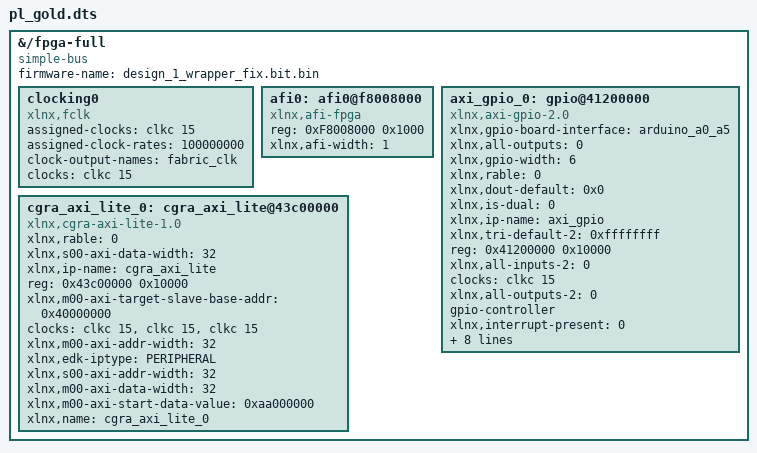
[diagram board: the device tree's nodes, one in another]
/dts-v1/;
/plugin/;

/ {
	fragment@0 {
		target-path = "/fpga-full";
		__overlay__ {
			ranges;
			compatible = "simple-bus";
			#address-cells = <1>;
			#size-cells = <1>;
			firmware-name = "design_1_wrapper_fix.bit.bin";
			clocking0: clocking0 {
				compatible = "xlnx,fclk";
				assigned-clocks = <&clkc 15>;
				assigned-clock-rates = <100000000>;
				#clock-cells = <0>;
				clock-output-names = "fabric_clk";
				clocks = <&clkc 15>;
			};
			afi0: afi0@f8008000 {
				status = "okay";
				compatible = "xlnx,afi-fpga";
				#address-cells = <1>;
				reg = <0xF8008000 0x1000>;
				#size-cells = <0>;
				xlnx,afi-width = <1>;
			};
			axi_gpio_0: gpio@41200000 {
				xlnx,gpio-board-interface = "arduino_a0_a5";
				compatible = "xlnx,axi-gpio-2.0" , "xlnx,xps-gpio-1.00.a";
				xlnx,all-outputs = <0>;
				#gpio-cells = <2>;
				xlnx,gpio-width = <6>;
				xlnx,rable = <0>;
				xlnx,dout-default = <0x0>;
				xlnx,is-dual = <0>;
				xlnx,ip-name = "axi_gpio";
				xlnx,tri-default-2 = <0xffffffff>;
				reg = <0x41200000 0x10000>;
				xlnx,all-inputs-2 = <0>;
				clocks = <&clkc 15>;
				xlnx,all-outputs-2 = <0>;
				gpio-controller;
				xlnx,interrupt-present = <0>;
				xlnx,gpio2-board-interface = "Custom";
				xlnx,edk-iptype = "PERIPHERAL";
				xlnx,dout-default-2 = <0x0>;
				status = "okay";
				xlnx,gpio2-width = <32>;
				clock-names = "s_axi_aclk";
				xlnx,use-board-flow;
				xlnx,tri-default = <0xffffffff>;
				xlnx,name = "axi_gpio_0";
				xlnx,all-inputs = <0>;
			};
			cgra_axi_lite_0: cgra_axi_lite@43c00000 {
				compatible = "xlnx,cgra-axi-lite-1.0";
				xlnx,rable = <0>;
				xlnx,s00-axi-data-width = <32>;
				xlnx,ip-name = "cgra_axi_lite";
				reg = <0x43c00000 0x10000>;
				xlnx,m00-axi-target-slave-base-addr = <0x40000000>;
				clocks = <&clkc 15>, <&clkc 15>, <&clkc 15>;
				xlnx,m00-axi-addr-width = <32>;
				xlnx,edk-iptype = "PERIPHERAL";
				status = "okay";
				clock-names = "clk_i" , "m00_axi_aclk" , "s00_axi_aclk";
				xlnx,s00-axi-addr-width = <32>;
				xlnx,m00-axi-data-width = <32>;
				xlnx,m00-axi-start-data-value = <0xaa000000>;
				xlnx,name = "cgra_axi_lite_0";
			};
		}; /* close __overlay__ */
	}; /* close fragment@0 */
}; /* close root */
